# MEC1721N_B0_LJ register map
Vendor: Microchip Technology; Series: MEC172x; File version: 0
CPU: CM4 r1p0, little endian, MPU, FPU, 3 interrupt priority bits, 172 interrupts
Registers are 32-bit, read-write, reset 0x0 unless marked. A register's access mark holds for its fields unless they carry their own. Offsets are from the block's base; [hi:lo] are bit positions; lines under a group give offsets from that group; {n}, {i} and the like mark numbered series; 'fields as' and 'values as' point back to an identical list.

## SAFBC_EC — SAF BRIDGE COMPONENT
Base 0x40008000
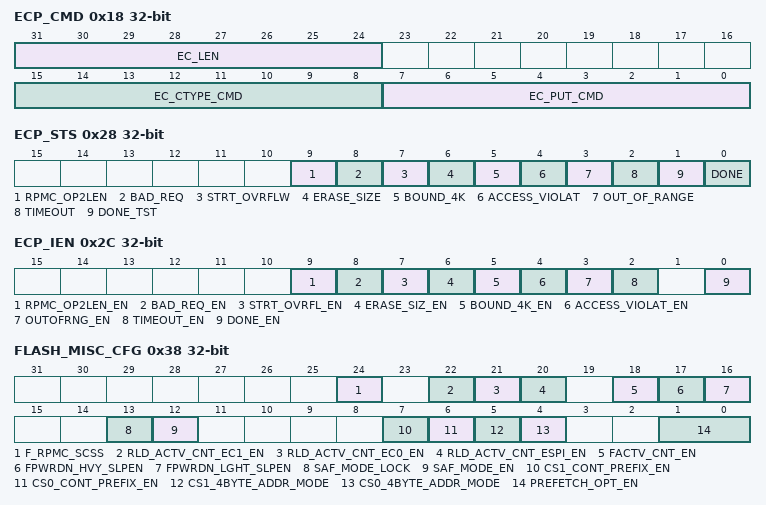
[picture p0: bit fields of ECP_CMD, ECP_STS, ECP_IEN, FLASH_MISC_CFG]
0x18 ECP_CMD — This register defines the command type and length of transfers requested by EC firmware
  [31:24] EC_LEN — This field contains the Length field for all requests. Read or Write or RPMC OP1 or OP2: The length in bytes of the data transfer, to or from the SRAM buffer. Must be in the range 1 -- 64 (01h -- 40h). Erase: Must encode an eSPI-defined Erase Block Size: 00h = 4K 01h = 32K 02h = 64K Other encodings are undefined.
  [15:8] EC_CTYPE_CMD — This field encodes the operation requested: 00h = Read 01h = Write (Page Program) 02h = Erase 03h = RPMC OP1 directed to Flash CS0# 04h = RPMC OP2 directed to Flash CS0# 83h = RPMC OP1 directed to Flash CS1# 84h = RPMC OP2 directed to Flash CS1# Other encodings are undefined
  [7:0] EC_PUT_CMD — This field must contain the value 0Ah; that is, the eSPI command PUT_FLASH_NP.
0x1C ECP_FLASH_ADDR — This register hold the Flash Space address to be accessed by the current command from EC firmware.
  [31:0] ADDR — FLASH_ADDR: This field holds the Flash address to be accessed.
0x20 ECP_START — This register contains the Start control for a Flash access requested in the rest of the EC Portal registers. It triggers the requested transfer.
  [0] START — This bit is written with '1' to start a new request, but always appears '0' when being read. Writing '1' to this bit immediately sets the EC_BUSY bit to '1' as an acknowledgement that the request is being serviced. Writing '1' to the START bit again, while the EC_BUSY bit is already '1' will do nothing except to set the START_OVERFLOW error status bit to '1' and the request already in service will complete normally except for the START_OVERFLOW=1 status indication.
0x24 ECP_BUF_ADDR — This register holds a location in the EC's own address space that is to be used as the SRAM buffer for an EC Flash access.
  [31:2] ADR — This field holds bits [31:2] of the SRAM buffer address. Bits[1:0] of the address are fixed at 00.
0x28 ECP_STS — This register holds the DONE status bit.
  [9] RPMC_OP2LEN — This bit indicates that a lenght greater that 49 is set for RPMC OP2 command. This is R/WC.
  [8] BAD_REQ — This bit indicates that an invalid Request code has been specified in the Portal Command Register at the time the START bit was set to trigger it. This bit is cleared by writing '1' to its position. This is R/WC.
  [7] STRT_OVRFLW — This bit indicates that an access was already in progress when a new access was requested by writing '1' to the START bit. Such a request is ignored except to set this bit. This bit is cleared by writing '1' to its position. This is R/WC.
  [6] ERASE_SIZE — This bit indicates that an invalid Erase Block Size has been specified in an Erase request from the EC. This error is detected by seeing 00h in the specific Erase Size opcode field. This bit is cleared by writing '1' to its position. This is R/WC.
  [5] BOUND_4K — This bit indicates that a Read request from the EC has been rejected because it has attempted to cross a 4K Flash address boundary. This bit is cleared by writing '1' to its position. This is R/WC.
  [4] ACCESS_VIOLAT — This bit indicates that a request from the EC has been rejected because it violates the Protection Register settings. This bit is cleared by writing '1' to its position. This is R/WC.
  [3] OUT_OF_RANGE — This bit indicates that a request from the EC has been rejected because it is beyond the physical limits of the attached Flash devices, as declared in the Size Limit and Threshold Registers. This bit is cleared by writing '1' to its position. This is R/WC.
  [2] TIMEOUT — This bit indicates that an Erase or Write or RPMC OP1 request from the EC has failed because the Flash has timed out. This bit is cleared by writing '1' to its position. This is R/WC.
  [1] DONE_TST — This bit is set to '1' by hardware during a requested access by the EC. It has no usage except for possible diagnostic purposes, but should be cleared (with the rest of this register) by writing '1' before starting any new access. This is R/WC.
  [0] DONE — This bit is set to '1' by hardware to indicate the end of a requested access by the EC. It can be enabled to trigger an interrupt when '1'. Writing a '1' clears this bit and the interrupt source. This is R/WC.
0x2C ECP_IEN — This register contains the one bit DONE_EN in bit position[0]. This bit enables the DONE bit in the status register to trigger an interrupt.
  [9] RPMC_OP2LEN_EN — This controls whether an interrupt is fired when RPMC OP2 Lenght is asserted.
  [8] BAD_REQ_EN — This controls whether an interrupt is fired when Bad Request is asserted.
  [7] STRT_OVRFL_EN — This controls whether an interrupt is fired when Start Overflow is asserted.
  [6] ERASE_SIZ_EN — This controls whether an interrupt is fired when Erase Size Error is asserted.
  [5] BOUND_4K_EN — This controls whether an interrupt is fired when 4K Boundary is asserted.
  [4] ACCESS_VIOLAT_EN — This controls whether an interrupt is fired when Access Violation is asserted.
  [3] OUTOFRNG_EN — This controls whether an interrupt is fired when Out Of Range is asserted.
  [2] TIMEOUT_EN — This controls whether an interrupt is fired when Timeout is asserted.
  [0] DONE_EN — This bit enables interrupts from the DONE bit in the Status register. 1 = Enabled 0 = Disabled
0x30 FLASH_SIZE_LIM — This register declares the address of the final byte of the Flash space implemented in the physically present Flash device or devices.
  [31:0] LIMIT
0x34 FLASH_THR — This register declares whether there are two Flash devices, and if so, where the boundary is between the devices.
  [31:0] THRES — The address placed in this register is the address of the first byte of the second Flash device. If there is only one Flash device, then this register must contain a value greater than the Size Limit register above.
0x38 FLASH_MISC_CFG — Bits[7:6] (PREFIX) declare the need for some Flash devices (notably Micron) to be given an explicit command to enter Continuous Mode, as opposed to requiring only Mode bits in the first Read access.
  [24] F_RPMC_SCSS — Force RPMC Success. 1=Forces all RPMC OP1 operations to be reported as successful.
  [22] RLD_ACTV_CNT_EC1_EN — Enables the activity counter to reload on EC1 Activity
  [21] RLD_ACTV_CNT_EC0_EN — Enables the activity counter to reload on EC0 Activity Counter Reload
  [20] RLD_ACTV_CNT_ESPI_EN — Enables the Activity Counter to Reload On SPI Enable
  [18] FACTV_CNT_EN — Enables the saf block to sleep on the Activity Counter reaching zero.
  [17] FPWRDN_HVY_SLPEN — Enables the SAF block to sleep the flash on Heavy Sleep Enable
  [16] FPWRDN_LGHT_SLPEN — Enables the SAF block to sleep the flash on Light Sleep Enable
  [13] SAF_MODE_LOCK — 0=The SAF Bridge register sets are unlocked and available R/W to EC firmware. 1=The SAF Bridge register sets Device Configuration and Device Timing, including this register, are locked read-only to EC firmware.
  [12] SAF_MODE_EN — 0=SAFS Mode operation is globally disabled. 1=SAFS Mode operation is globally enabled. The Captive QMSPI Block register set and the SAF Communication register set also become inaccessible to EC firmware.
  [7] CS1_CONT_PREFIX_EN — Declares whether the Flash device on CS1# (if any) requires a prefix command to enter Continuous Mode. 0=No prefix command is required by the Flash device on CS1#. 1=A Prefix command will be issued from the CS1 fields of the SAF Flash Configuration Special Mode Register to the Flash device on CS1# before entry into Continuous Mode.
  [6] CS0_CONT_PREFIX_EN — Declares whether the Flash device on CS0# requires a prefix command to enter Continuous Mode. 0=No prefix command is required by the Flash device on CS0#. 1=A Prefix command will be issued from the CS0 fields of the SAF Flash Configuration Special Mode Register to the Flash device on CS0# before entry into Continuous Mode.
  [5] CS1_4BYTE_ADDR_MODE — Declares whether the Flash device on CS1# uses a 32-bit address. Set this bit to '1' if the Flash device is 32Mbytes (256MBits) or greater. This bit does not cause the Flash device itself to be placed into 4-byte address mode; that must be done by EC firmware before enabling SAFS operation. 0=Issue 3-byte addresses to the CS1# Flash device. 1=Issue 4-byte addresses to the CS1# Flash device.
  [4] CS0_4BYTE_ADDR_MODE — Declares whether the Flash device on CS0# uses a 32-bit address. Set this bit to '1' if the Flash device is 32Mbytes (256MBits) or greater. This bit does not cause the Flash device itself to be placed into 4-byte address mode; that must be done by EC firmware before enabling SAFS operation. 0=Issue 3-byte addresses to the CS0# Flash device. 1=Issue 4-byte addresses to the CS0# Flash device.
  [1:0] PREFETCH_OPT_EN — Selects optimized data prefetching from the Flash devices to the eSPI Master. This field has no effect unless the PREFETCH_EN bit is also '1' 00= Prefetched data from Flash is delivered using canonical eSPI methods. (Default) 11= Prefetched data from Flash is delivered using expedited eSPI methods. 01,10= (Reserved)
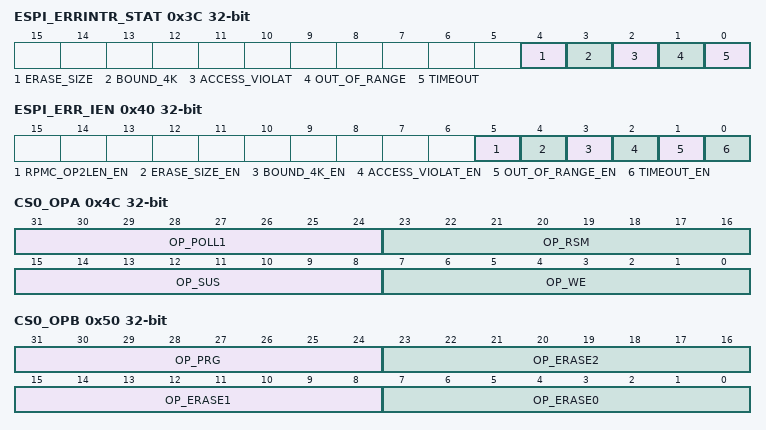
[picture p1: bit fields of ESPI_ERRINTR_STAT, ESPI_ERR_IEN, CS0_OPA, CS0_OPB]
0x3C ESPI_ERRINTR_STAT — These bits may be individually enabled to trigger interrupts using the corresponding Interrupt Enable register.
  [4] ERASE_SIZE — This bit indicates that an invalid Erase Block Size has been specified in an Erase request from the Host Chipset. This bit is cleared by writing '1' to its position. This is R/WC.
  [3] BOUND_4K — This bit indicates that a Read request from the Host Chipset has been rejected because it has attempted to cross a 4K Flash address boundary. This bit is cleared by writing '1' to its position. This is R/WC.
  [2] ACCESS_VIOLAT — This bit indicates that a request from the Host Chipset has been rejected because it violates the Protection Register settings. This bit is cleared by writing '1' to its position. This is R/WC.
  [1] OUT_OF_RANGE — This bit indicates that a request from the Host Chipset has been rejected because it is beyond the physical limits of the attached Flash devices. This bit is cleared by writing '1' to its position. This is R/WC.
  [0] TIMEOUT — This bit indicates that an Erase or Write request from the Host Chipset has failed because the Flash has timed out. This bit is cleared by writing '1' to its position. This is R/WC.
0x40 ESPI_ERR_IEN — This is the eSPI Error interrupt Enable Register.
  [5] RPMC_OP2LEN_EN — This bit enables the RPMC OP2 Length Error status bit as an interrupt.
  [4] ERASE_SIZE_EN — This bit enables the ERASE_SIZE status bit as an interrupt.
  [3] BOUND_4K_EN — This bit enables the 4K_BOUNDARY status bit as an interrupt.
  [2] ACCESS_VIOLAT_EN — This bit enables the ACCESS_VIOLATION status bit as an interrupt.
  [1] OUT_OF_RANGE_EN — This bit enables the OUT_OF_RANGE status bit as an interrupt.
  [0] TIMEOUT_EN — This bit enables the TIMEOUT status bit as an interrupt.
0x44 EC_BUSY — This register holds the EC_BUSY status bit, which indicates when the EC Portal is busy performing an access.
  [0] EC_BUSY — This Read-Only bit is set to '1' by hardware when the START bit is written with '1' to start a new request. It is cleared to '0' when request completes, and its falling edge sets the DONE bit. While this bit is '1', the EC Portal Command, Flash Address and Buffer Address registers are locked Read-Only, and the START bit is disabled, causing it only to set the START_OVERFLOW error status bit to '1'.
0x4C CS0_OPA — There are two Opcode A registers, one associated with each of the Flashes. If the CS1 Flash does not exist, its register can be left in its default state. The four fields in each register represent the 8-bit Flash opcodes for Write Enable, Suspend, Resume and Read Status Register. The Status Register referred to is the register inside the Flash which contains the (BUSY) or (IN PROGRESS) status bit in position 0.
  [31:24] OP_POLL1 — This field contains the 8-bit Opcode for Read Status Register in the respective Flash device.
  [23:16] OP_RSM — This field contains the 8-bit Opcode for Resume in the respective Flash device.
  [15:8] OP_SUS — This field contains the 8-bit Opcode for Suspend in the respective Flash device.
  [7:0] OP_WE — This field contains the 8-bit Opcode for Write Enable in the respective Flash device.
0x50 CS0_OPB — There are two Opcode B registers, one associated with each of the Flashes. If the CS1 Flash does not exist, its register can be left in its default state. The OP_PROGRAM field is mandatory, and must hold the Page Program opcode for the respective Flash. The Erase size of 4K is mandatory, and so the OP_ERASE0 field must be initialized to the appropriate opcode for the Flash device. There is only one bit declaring each Erase size up to the Host System (instead of one per Flash device, see eSPI Configuration Register 44h), so if there are two Flash devices, each Erase size over 4K must be declared here only if BOTH Flash devices support it.
  [31:24] OP_PRG — This field contains the 8-bit Opcode for Page Program in the respective Flash device.
  [23:16] OP_ERASE2 — This field contains the 8-bit Opcode for 64K Erase in the respective Flash device. If there are two Flash devices present, and 64K Erase is not supported by both Flash devices, then this field must be left as 00h in both the CS0 and CS1 registers.
  [15:8] OP_ERASE1 — This field contains the 8-bit Opcode for 32K Erase in the respective Flash device. If there are two Flash devices present, and 32K Erase is not supported by both Flash devices, then this field must be left as 00h in both the CS0 and CS1 registers.
  [7:0] OP_ERASE0 — This field contains the 8-bit Opcode for 4K Erase in the respective Flash device. This Erase size is mandatory.
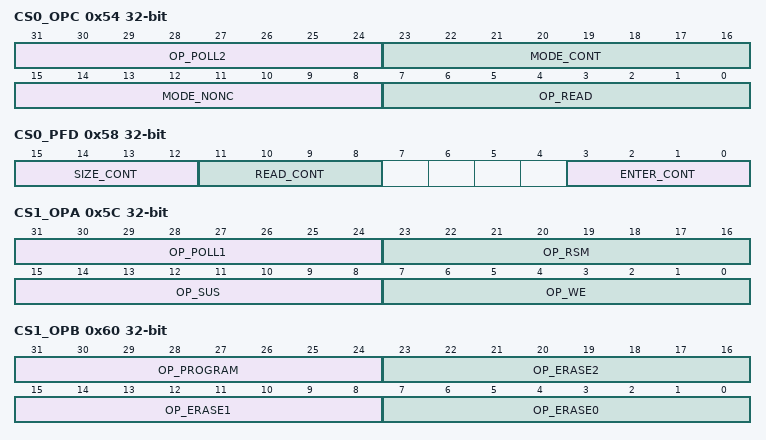
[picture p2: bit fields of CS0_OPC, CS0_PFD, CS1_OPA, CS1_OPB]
0x54 CS0_OPC — There are two Opcode C registers, one associated with each of the Flashes. If the CS1 Flash does not exist, its register can be left in its default state. Two fields (OP) define opcodes, and two fields (MODE) represent the Mode code values. Mode codes are provided immediately after the Address in Continuous Read traffic, and are used to keep the Flash device in Continuous Read Mode. Depending on the Flash device manufacturer, this mode may be documented in their datasheet as either a Mode byte, or as certain bits of a first Dummy byte or first Dummy clock. The recommended Mode values given below are selected to be appropriate for any Flash device.
  [31:24] OP_POLL2 — This field contains the 8-bit Opcode used to confirm Suspended status in the Flash device. It is issued using a designated Timing Descriptor chain Poll which is used to read a 16-bit value. This value is evaluated using the Mask values in the Poll2 Mask register
  [23:16] MODE_CONT — This field contains the 8-bit Mode code used to place (or keep) the Flash device in Continuous Read mode. It is strongly recommended that this value be set to A5h, as a universally-acceptable value among Flash devices.
  [15:8] MODE_NONC — This field is currently a placeholder and is not used. The recommended value for this field, for future compatibility, is FFh.
  [7:0] OP_READ — This field must contain the 8-bit Opcode for Fast Read Quad or Fast Read Dual in the respective Flash device. This code is used in entering Continuous Read mode, and does not appear afterward.
0x58 CS0_PFD — There are two Per-Flash Descriptors registers, one associated with each of the Flash devices.
  [15:12] SIZE_CONT — This field points to the Descriptor element within the READ_CONT chain that contains the Length field for data.
  [11:8] READ_CONT — This field points to the first Descriptor element of the Continuous Read chain.
  [3:0] ENTER_CONT — This field points to the first Descriptor element of the Enter Continuous Mode chain.
0x5C CS1_OPA — This is the CS1 Opcode A register. If the CS1 Flash does not exist, its register can be left in its default state. The four fields in each register represent the 8-bit Flash opcodes for Write Enable, Suspend, Resume and Read Status Register. The Status Register referred to is the register inside the Flash which contains the BUSY or IN PROGRESS status bit in position 0.
  fields as CS0_OPA
0x60 CS1_OPB — This is the CS1 Flash Opcode B register. If the CS1 Flash does not exist, its register can be left in its default state. The OP_PROGRAM field is mandatory, and must hold the Page Program opcode for the respective Flash. The Erase size of 4K is mandatory, and so the OP_ERASE0 field must be initialized to the appropriate opcode for the Flash device. There is only one bit declaring each Erase size up to the Host System (instead of one per Flash device, see eSPI Configuration Register 44h), so if there are two Flash devices, each Erase size over 4K must be declared here only if BOTH Flash devices support it.
  [31:24] OP_PROGRAM — This field contains the 8-bit Opcode for Page Program in the respective Flash device.
  [23:16] OP_ERASE2 — This field contains the 8-bit Opcode for 64K Erase in the respective Flash device. If there are two Flash devices present, and 64K Erase is not supported by both Flash devices, then this field must be left as 00h in both the CS0 and CS1 registers.
  [15:8] OP_ERASE1 — This field contains the 8-bit Opcode for 32K Erase in the respective Flash device. If there are two Flash devices present, and 32K Erase is not supported by both Flash devices, then this field must be left as 00h in both the CS0 and CS1 registers.
  [7:0] OP_ERASE0 — This field contains the 8-bit Opcode for 4K Erase in the respective Flash device. This Erase size is mandatory.
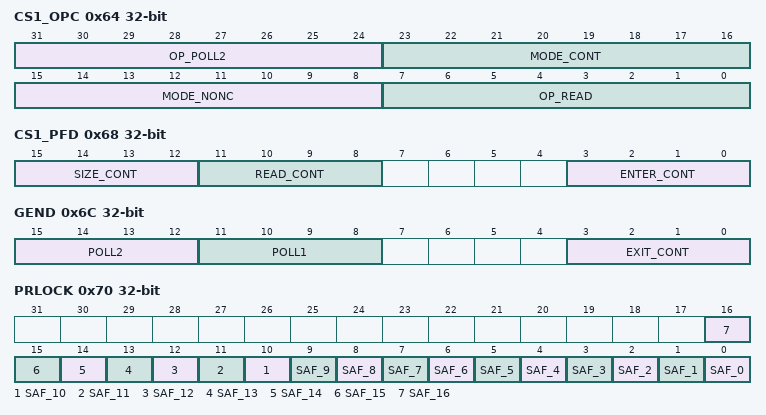
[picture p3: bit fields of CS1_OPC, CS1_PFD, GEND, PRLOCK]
0x64 CS1_OPC — This is the CS1 Flash device Opcode C register. If the CS1 Flash does not exist, its register can be left in its default state. Two fields (OP) define opcodes, and two fields (MODE) represent the Mode code values. Mode codes are provided immediately after the Address in Continuous Read traffic, and are used to keep the Flash device in Continuous Read Mode. Depending on the Flash device manufacturer, this mode may be documented in their datasheet as either a Mode byte, or as certain bits of a first Dummy byte or first Dummy clock. The recommended Mode values given below are selected to be appropriate for any Flash device.
  fields as CS0_OPC
0x68 CS1_PFD — This is the Per-Flash Descriptors register for CS1 Flash.
  fields as CS0_PFD
0x6C GEND — This is a single register, which accompanies the two Per-Flash Descriptors registers, and provides Descriptor pointers that are shared by both CS0 and CS1 devices uniformly. Each 4-bit field is a pointer which identifies a Timing Descriptor location in the Captive QMSPI block's memory. The EXIT_CONT field (Exit Continuous Mode) points to the single chain invoked to exit the Flash from Continuous Mode, allowing an Erase or Program command to be entered. This chain is identical for either Flash device, regardless of its manufacturer, and simply directs a universal Exit symbol to the appropriate CS0/CS1 device. The POLL1 and POLL2 fields should both point to the same chain. This chain will issue the appropriate opcode for the operation (Poll1 or Poll2) supplied by the SAF Bridge from the Opcode registers, and will read back 16 bits of information for use by the SAF Bridge.
  [15:12] POLL2 — This field points to the first Descriptor element of the Poll chain, used when polling for Suspended status.
  [11:8] POLL1 — This field points to the first Descriptor element of the Poll chain, used when polling for Busy status.
  [3:0] EXIT_CONT — This field points to the first Descriptor element of the Exit Continuous Mode chain.
0x70 PRLOCK — There is a bit in this register for each of the 17 Protection Region Register sets. Writing '1' to a bit locks the associated 4-Register set to Read-Only access, and also locks this bit itself to a Read-Only '1'.
  [n] SAF_{n} (n=0..16) — In its initial 0 state, this bit allows Read and Write access to the corresponding Region Register set RR = {n}: Start, Limit, Write and Read. When written to 1, this bit locks those four registers as read-only, and also locks this bit itself against being cleared.
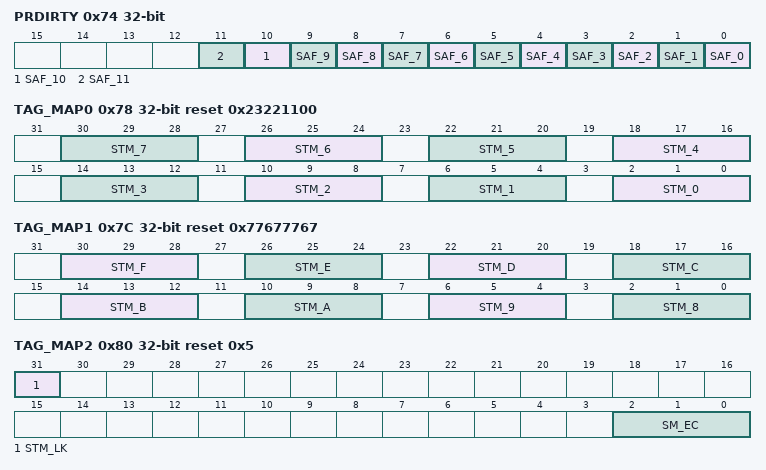
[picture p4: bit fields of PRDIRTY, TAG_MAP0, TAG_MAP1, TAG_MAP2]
0x74 PRDIRTY — There is a bit in this register for each of the 12 Flash Regions that can be allocated from the Region Table in the Intel Descriptor structure. Register sets 12 through 16 do not represent allocated Flash regions, and so they do not have bits in this register.
  [n] SAF_{n} (n=0..11) — Indicates whether contents of Region {n} have been changed. 0=There has been no Write or Erase performed in this region since this bit was last cleared. 1=A Write or Erase has been performed in this region since this bit was last cleared.
0x78 TAG_MAP0 reset 0x23221100 — The default values in this register match hard-wired assignments made in the Chipset for eSPI Tag values 0h through 7h. A default value of 7 indicates a non-existent map entry, for a Tag value which should never happen.
  [4n+2:4n] STM_{n} (n=0..7) — This bit contains the mapping of the 4-bit eSPI Tag value {n}h to its 3-bit Protection Master number.
0x7C TAG_MAP1 reset 0x77677767 — The default values in this register match hard-wired assignments made in the Chipset for eSPI Tag values 8h through Fh. A default value of 7 indicates a non-existent map entry, for a Tag value which should never happen.
  [30:28] STM_F — This bit contains the mapping of the 4-bit eSPI Tag value Fh to its 3-bit Protection Master number.
  [26:24] STM_E — This bit contains the mapping of the 4-bit eSPI Tag value Eh to its 3-bit Protection Master number.
  [22:20] STM_D — This bit contains the mapping of the 4-bit eSPI Tag value Dh to its 3-bit Protection Master number.
  [18:16] STM_C — This bit contains the mapping of the 4-bit eSPI Tag value Ch to its 3-bit Protection Master number.
  [14:12] STM_B — This bit contains the mapping of the 4-bit eSPI Tag value Bh to its 3-bit Protection Master number.
  [10:8] STM_A — This bit contains the mapping of the 4-bit eSPI Tag value Ah to its 3-bit Protection Master number.
  [6:4] STM_9 — This bit contains the mapping of the 4-bit eSPI Tag value 9h to its 3-bit Protection Master number.
  [2:0] STM_8 — This bit contains the mapping of the 4-bit eSPI Tag value 8h to its 3-bit Protection Master number.
0x80 TAG_MAP2 reset 0x5 — The default value in bits [2:0] of this register matches the hard-wired assignment made in the Chipset for accesses made by an EC. After ensuring that all three Tag Map Registers [2:0] contain valid mappings, the STM_LK bit should be set to '1' to lock them, preventing firmware from re-assigning them later.
  [31] STM_LK — 1 Locks all bits in the Tag Map Registers, including this bit. 0 (Default) keeps all Tag Map Register fields R/W.
  [2:0] SM_EC — This bit maps the 3-bit Protection Master number assigned to EC Firmware accesses.
{0x84+0x10*i} SAF_PROT[{i}] (i=0..16) group
  0x00 START reset 0x7FFF — This is Start00 register. Unless the Start register is less than or equal to the Limit register, the associated register set [RR] is Disabled, and has no effect on permissions. The default state of these registers, in all of the register sets, is this Disabled state. While all register sets remain Disabled, no Protection Master except Master #0 (PCH HW) will be able to perform any Flash access anywhere through SAFS operations, and this restriction includes the EC firmware (as Master #5).
    [19:0] SAF_PROT — This field contains the start address of this Region, in units of 4K bytes.
  0x04 LIMIT — This is Limit00 register. Unless the Start register is less than or equal to the Limit register, the associated register set [RR] is Disabled, and has no effect on permissions. The default state of these registers, in all of the register sets, is this Disabled state. While all register sets remain Disabled, no Protection Master except Master #0 (PCH HW) will be able to perform any Flash access anywhere through SAFS operations, and this restriction includes the EC firmware (as Master #5).
    [19:0] SAF_PROT — This field contains the limit address of this Region, in units of 4K bytes. The entire 4K block identified is within the Region: that is, the final byte address is determined by appending FFFh to this field.
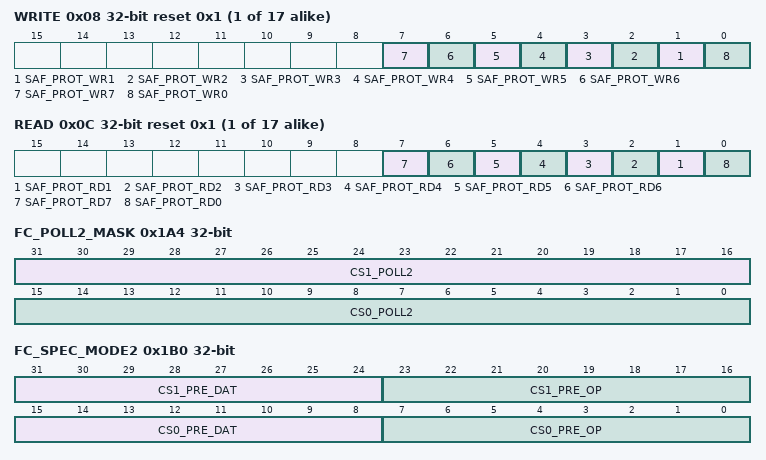
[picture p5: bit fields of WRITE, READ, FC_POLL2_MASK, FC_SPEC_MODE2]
  0x08 WRITE reset 0x1 — This is Write00 register. It applies to the region defined by the associated [RR] Start and Limit registers. Bits at positions [0]--[7] grant Write/Erase permission to Permission Masters numbered 0--7 respectively.
    [n] SAF_PROT_WR{n} (n=1..7) — This bit contains the permission for Write or Erase access by Protection Master {n} to this Region. 0=Protection Master {n} may not Write or Erase in this region. 1=Protection Master {n} may Write and Erase in this region.
    [0] SAF_PROT_WR0 — This bit contains the permission for Write or Erase access by Protection Master 0 to this Region. It is a read-only '1' placeholder because Protection Master 0 has full access to all Flash locations. 1=Protection Master 0 may always Write and Erase in this region.
  0x0C READ reset 0x1 — This is Read00 register. Bits at positions [0]--[7] grant Read permission to Permission Masters numbered 0--7 respectively.
    [n] SAF_PROT_RD{n} (n=1..7) — This bit contains the permission for Read access by Protection Master {n} to this Region. 0=Protection Master {n} may not Read in this region. 1=Protection Master {n} may Read in this region.
    [0] SAF_PROT_RD0 — This bit contains the permission for Read access by Protection Master 0 to this Region. It is a read-only placeholder because Protection Master 0 has full access to all Flash locations. 1=Protection Master 0 may always Read in this region.
0x194 POLL_TMOUT — This is an error timeout value imposed on any consecutive series of Poll-1 commands to a Flash. The timeout counter starts whenever any new Poll-1 sequence starts, and stops when a Poll-1 detects Not-BUSY status from the Flash.
  [17:0] TOUT — This field provides a polling timeout value in units of the 32KHz clock. Recommended value is 5 seconds, expressed as 28000h (163,840 decimal) in this field.
0x198 POLL_INTRVL — This register should be kept zero except for diagnostic purposes. Where needed, it can be set to provide spacing between consecutive Poll-1 operations to limit the amount of traffic.
  [15:0] INTRVL — This field provides an interval in units of the EC internal clock MCLK.
0x19C SUSP_RES_INTRVL reset 0x1 — The value placed in this register provides necessary programmable support to a Flash that is performing an Erase or a Program operation. When an Erase or Program is started or Resumed, a Suspend is held off until this time expires. While an Erase or Program is in process but Suspended, a Resume is forced when this time expires, even if Read requests are still pending, causing the Erase or Program operation to continue, and again inhibiting the next Suspend until it expires again.
  [15:0] INTRVL — This field provides an interval value in units of the 32KHz RTC clock. Its value should be taken from the Flash datasheet parameter that specifies minimum time for an Erase or Program step to make progress.
0x1A0 CONSEC_RD_TMOUT — This register is used to detect when a series of Read transfers has finished. When this time expires without any new Read request, any suspended Erase or Program operation is given the Resume command to continue.
  [19:0] RD_TOUT — This field provides a timeout value in units of the EC internal clock MCLK. This value is tunable for system performance, but a value at or below 20us is suggested.
0x1A4 FC_POLL2_MASK — Upon issuing a Suspend command, a Poll-1 operation is repeated until the Flash is no longer BUSY, then a Poll-2 operation to determine whether the Flash device is in a Suspended state.
  [31:16] CS1_POLL2 — A '1' in this field masks out (ignores) the corresponding bit returned in Poll-2 status for the CS1 Flash.
  [15:0] CS0_POLL2 — A '1' in this field masks out (ignores) the corresponding bit returned in Poll-2 status for the CS0 Flash.
0x1A8 FC_SPEC_MODE — This register provides special mode control.
  [0] DIS_SUSPEND — A '1' in this field enters DISABLE_SUSPEND mode, which prevents suspending an Erase or Write in progress. In this mode, Read operations will be held waiting until the Erase or Write finishes.
0x1AC SUSP_CHECK_DLY — This register provides a time delay for support of some Flash devices. It holds off the first Poll-1 check after a Suspend command has been given to the Flash.
  [19:0] DLY — This field provides a delay value in units of the EC internal clock MCLK. This value should be set to 20us.
0x1B0 FC_SPEC_MODE2 — Micron requires a prefix consisting of two command frames (in separate CS# assertions) to be sent before Mode information will be recognized to enter Continuous Read mode. This technique is called (Micron XIP) in their datasheets. The support for these chips requires setting up this register and setting the corresponding Prefix Enable bit(s) to enable this handling. The first command frame of the Prefix sequence will be a single byte consisting of the Write Enable opcode, taken from the OP_WE opcode field of the appropriate Opcode A register (Section 7.3.5, on page 113). The second command frame of the Prefix sequence comes from this register, consisting of first the PREFIX_OP byte for the corresponding Flash device (CS0/CS1), and then its PREFIX_DAT byte. The PREFIX_OP byte will be 81h always, which is documented as the Micron opcode (WRITE VOLATILE CONFIGURATION REGISTER) The PREFIX_DAT byte contains the data written to the Micron Flash device's Volatile Configuration Register. It has potential side-effects beyond just enabling Micron XIP Mode, so it must be constructed very carefully.
  [31:24] CS1_PRE_DAT — This field is the data sent with the CS1_PREFIX_OP command.
  [23:16] CS1_PRE_OP — This field is the Prefix Opcode for Micron XIP mode on CS1. It should be set to 81h, for Micron parts.
  [15:8] CS0_PRE_DAT — This field is the data sent with the CS0_PREFIX_OP command.
  [7:0] CS0_PRE_OP — This field is the Prefix Opcode for Micron XIP mode on CS0. It should be set to 81h, for Micron parts.
0x1B4 DNX_PRO_BYPAS — DnX DnX Protection Bypass Register.
  [28] DNX_LK — Lock bit for this register: 0= All Read/Write bits in this register are unlocked and writable. 1= All Read/Write bits in this register are locked to Read-Only (including this bit).
0x1B8 ACTV_CNT 16-bit — Timeout Activity Counter.
  [15:0] FT_ACTV_CNT — This is the Flash Avtivity Timeout Counter.
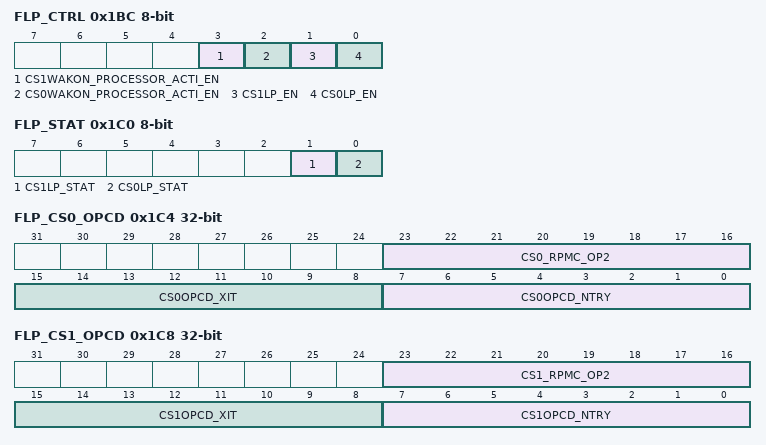
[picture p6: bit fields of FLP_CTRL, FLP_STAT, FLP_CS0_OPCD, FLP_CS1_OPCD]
0x1BC FLP_CTRL 8-bit — SAF Low Power Control Register.
  [3] CS1WAKON_PROCESSOR_ACTI_EN — Enable wake SPI Flash CS1 when processor wakes.
  [2] CS0WAKON_PROCESSOR_ACTI_EN — Enable wake SPI Flash CS0 when processor wakes.
  [1] CS1LP_EN — CS1 Low Power Enable.
  [0] CS0LP_EN — CS0 Low Power Enable.
0x1C0 FLP_STAT 8-bit — SAF Low Power Status Register.
  [1] CS1LP_STAT — CS1 Low Power Enable.
  [0] CS0LP_STAT — CS0 Low Power Status.
0x1C4 FLP_CS0_OPCD — SAF Low Power CS0 OPCODE Register.
  [23:16] CS0_RPMC_OP2 — CS0 Opcode for rpmc op2.
  [15:8] CS0OPCD_XIT — CS0 Low Power Opcode for low power exit.
  [7:0] CS0OPCD_NTRY — CS0 Low Power Opcode for low power entry.
0x1C8 FLP_CS1_OPCD — SAF Low Power CS0 OPCODE Register.
  [23:16] CS1_RPMC_OP2 — CS1 Opcode for rpmc op2.
  [15:8] CS1OPCD_XIT — CS1 Low Power Opcode for low power exit.
  [7:0] CS1OPCD_NTRY — CS1 Low Power Opcode for low power entry.
0x1CC FPD_TOUT_PDUP 16-bit — Flash Timeout Power Down Up.
  [15:0] FPD_TOUT_CNT — This is the Flash Timeout Power Down Up.
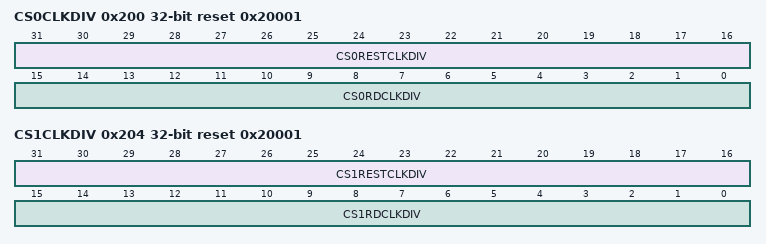
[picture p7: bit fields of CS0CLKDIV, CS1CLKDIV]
0x200 CS0CLKDIV reset 0x20001 — Clock Divider for CS0.
  [31:16] CS0RESTCLKDIV — Read clock divider for CS0.
  [15:0] CS0RDCLKDIV — Read clock divider for CS0.
0x204 CS1CLKDIV reset 0x20001 — Clock Divider for CS1.
  [31:16] CS1RESTCLKDIV — Read clock divider for CS1.
  [15:0] CS1RDCLKDIV — Read clock divider for CS1.
0x208 ESPIRPMCOP2_RESADD — eSPI RPMC OP2 Result Address.
  [31:0] EC0RPMCOP2_RESADD — eSPI RPMC OP2 Result Address for EC0.
0x20C EC0RPMCOP2_RESADD — EC0 RPMC OP2 Result Address.
  [31:0] EC0RPMCOP2_RESADD — eSPI RPMC OP2 Result Address for EC0.
0x210 EC1RPMCOP2_RESADD — EC1 RPMC OP2 Result Address.
  [31:0] EC1RPMCOP2_RESADD — eSPI RPMC OP2 Result Address for EC1.
